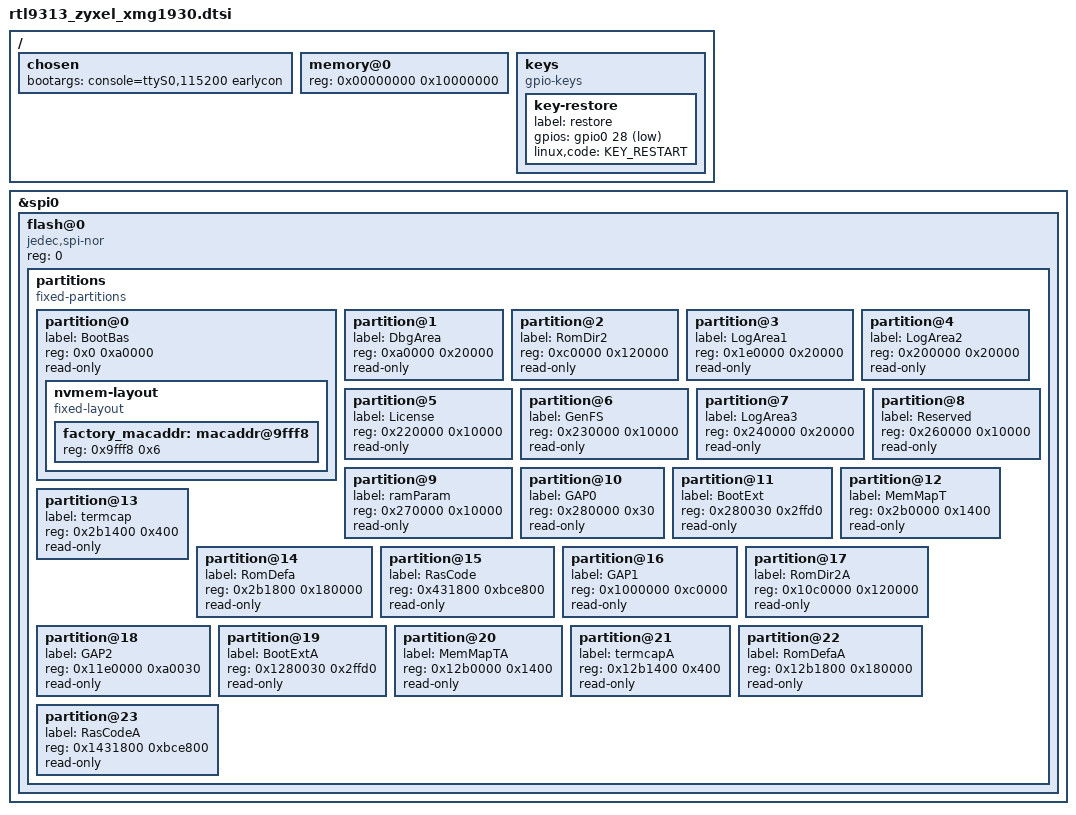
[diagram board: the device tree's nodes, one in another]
// SPDX-License-Identifier: GPL-2.0-or-later
/dts-v1/;

#include "rtl931x.dtsi"

#include <dt-bindings/input/input.h>
#include <dt-bindings/gpio/gpio.h>
#include <dt-bindings/leds/common.h>
#include <dt-bindings/mux/mux.h>

/ {
	chosen {
		bootargs = "console=ttyS0,115200 earlycon";
	};

	memory@0 {
		device_type = "memory";
		reg = <0x00000000 0x10000000>;
	};

	keys {
		compatible = "gpio-keys";

		key-restore {
			label = "restore";
			gpios = <&gpio0 28 GPIO_ACTIVE_LOW>;
			linux,code = <KEY_RESTART>;
		};
	};
};

&spi0 {
	status = "okay";

	flash@0 {
		compatible = "jedec,spi-nor";
		reg = <0>;

		partitions {
			compatible = "fixed-partitions";
			#address-cells = <1>;
			#size-cells = <1>;

			partition@0 {
				label = "BootBas";
				reg = <0x0 0xa0000>;
				read-only;

				nvmem-layout {
					compatible = "fixed-layout";
					#address-cells = <1>;
					#size-cells = <1>;

					factory_macaddr: macaddr@9fff8 {
						reg = <0x9fff8 0x6>;
					};
				};
			};
			partition@1 {
				label = "DbgArea";
				reg = <0xa0000 0x20000>;
				read-only;
			};
			partition@2 {
				label = "RomDir2";
				reg = <0xc0000 0x120000>;
				read-only;
			};
			partition@3 {
				label = "LogArea1";
				reg = <0x1e0000 0x20000>;
				read-only;
			};
			partition@4 {
				label = "LogArea2";
				reg = <0x200000 0x20000>;
				read-only;
			};
			partition@5 {
				label = "License";
				reg = <0x220000 0x10000>;
				read-only;
			};
			partition@6 {
				label = "GenFS";
				reg = <0x230000 0x10000>;
				read-only;
			};
			partition@7 {
				label = "LogArea3";
				reg = <0x240000 0x20000>;
				read-only;
			};
			partition@8 {
				label = "Reserved";
				reg = <0x260000 0x10000>;
				read-only;
			};
			partition@9 {
				label = "ramParam";
				reg = <0x270000 0x10000>;
				read-only;
			};
			/* GAP: 0x280000 - 0x28002f */
			partition@10 {
				label = "GAP0";
				reg = <0x280000 0x30>;
				read-only;
			};
			partition@11 {
				label = "BootExt";
				reg = <0x280030 0x2ffd0>;
				read-only;
			};
			partition@12 {
				label = "MemMapT";
				reg = <0x2b0000 0x1400>;
				read-only;
			};
			partition@13 {
				label = "termcap";
				reg = <0x2b1400 0x400>;
				read-only;
			};
			partition@14 {
				label = "RomDefa";
				reg = <0x2b1800 0x180000>;
				read-only;
			};
			partition@15 {
				label = "RasCode";
				reg = <0x431800 0xbce800>;
				read-only;
			};
			/* GAP: 0x1000000 - 0x10bffff */
			partition@16 {
				label = "GAP1";
				reg = <0x1000000 0xc0000>;
				read-only;
			};
			partition@17 {
				label = "RomDir2A";
				reg = <0x10c0000 0x120000>;
				read-only;
			};
			/* GAP: 0x11e0000 - 0x128002f */
			partition@18 {
				label = "GAP2";
				reg = <0x11e0000 0xa0030>;
				read-only;
			};
			partition@19 {
				label = "BootExtA";
				reg = <0x1280030 0x2ffd0>;
				read-only;
			};
			partition@20 {
				label = "MemMapTA";
				reg = <0x12b0000 0x1400>;
				read-only;
			};
			partition@21 {
				label = "termcapA";
				reg = <0x12b1400 0x400>;
				read-only;
			};
			partition@22 {
				label = "RomDefaA";
				reg = <0x12b1800 0x180000>;
				read-only;
			};
			partition@23 {
				label = "RasCodeA";
				reg = <0x1431800 0xbce800>;
				read-only;
			};


		};
	};
};
